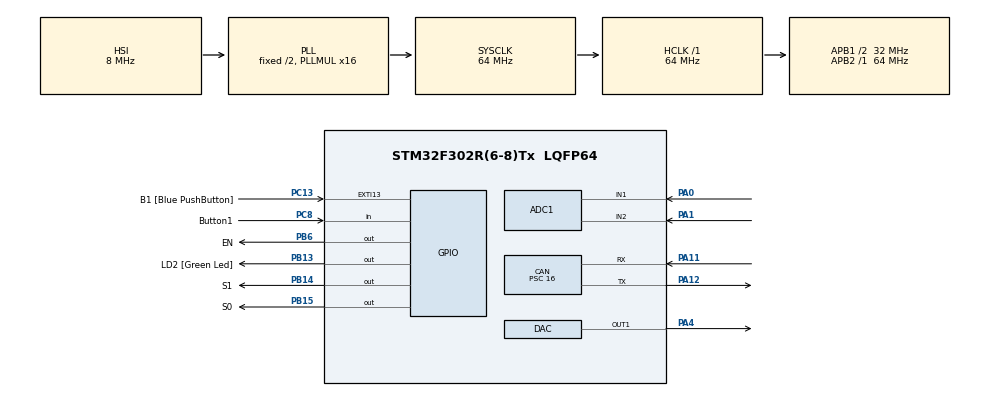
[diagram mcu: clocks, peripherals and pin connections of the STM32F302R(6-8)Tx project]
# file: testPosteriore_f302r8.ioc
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ADC1.Channel-0\#ChannelRegularConversion=ADC_CHANNEL_1
ADC1.Channel-1\#ChannelRegularConversion=ADC_CHANNEL_2
ADC1.ContinuousConvMode=ENABLE
ADC1.DMAContinuousRequests=ENABLE
ADC1.NbrOfConversion=2
ADC1.NbrOfConversionFlag=1
ADC1.Offset-0\#ChannelRegularConversion=0
ADC1.Offset-1\#ChannelRegularConversion=0
ADC1.OffsetNumber-0\#ChannelRegularConversion=ADC_OFFSET_NONE
ADC1.OffsetNumber-1\#ChannelRegularConversion=ADC_OFFSET_NONE
ADC1.Rank-0\#ChannelRegularConversion=1
ADC1.Rank-1\#ChannelRegularConversion=2
ADC1.SamplingTime-0\#ChannelRegularConversion=ADC_SAMPLETIME_61CYCLES_5
ADC1.SamplingTime-1\#ChannelRegularConversion=ADC_SAMPLETIME_61CYCLES_5
ADC1.SamplingTimeOPAMP-1\#ChannelRegularConversion=ADC_SAMPLETIME_61CYCLES_5
ADC1.SubFamily=STM32F302x8
ADC1.master=1
CAN.BS1=CAN_BS1_2TQ
CAN.CalculateBaudRate=500000
CAN.CalculateTimeBit=2000
CAN.CalculateTimeQuantum=500.0
CAN.Mode=CAN_MODE_NORMAL
CAN.Prescaler=16
Dma.ADC1.1.Direction=DMA_PERIPH_TO_MEMORY
Dma.ADC1.1.Instance=DMA1_Channel1
Dma.ADC1.1.MemDataAlignment=DMA_MDATAALIGN_HALFWORD
Dma.ADC1.1.MemInc=DMA_MINC_ENABLE
Dma.ADC1.1.Mode=DMA_CIRCULAR
Dma.ADC1.1.PeriphDataAlignment=DMA_PDATAALIGN_HALFWORD
Dma.ADC1.1.PeriphInc=DMA_PINC_DISABLE
Dma.ADC1.1.Priority=DMA_PRIORITY_LOW
Dma.DAC_CH1.0.Direction=DMA_MEMORY_TO_PERIPH
Dma.DAC_CH1.0.Instance=DMA1_Channel3
Dma.DAC_CH1.0.MemDataAlignment=DMA_MDATAALIGN_HALFWORD
Dma.DAC_CH1.0.MemInc=DMA_MINC_ENABLE
Dma.DAC_CH1.0.Mode=DMA_CIRCULAR
Dma.DAC_CH1.0.PeriphDataAlignment=DMA_PDATAALIGN_HALFWORD
Dma.DAC_CH1.0.PeriphInc=DMA_PINC_DISABLE
Dma.DAC_CH1.0.Priority=DMA_PRIORITY_LOW
Dma.Request0=DAC_CH1
Dma.Request1=ADC1
Mcu.Family=STM32F3
Mcu.Name=STM32F302R(6-8)Tx
Mcu.Package=LQFP64
NVIC.DMA1_Channel1_IRQn=true\:0\:0\:false\:false\:true\:false\:true\:true
NVIC.DMA1_Channel3_IRQn=true\:0\:0\:false\:false\:true\:false\:true\:true
NVIC.EXTI15_10_IRQn=true\:0\:0\:false\:false\:true\:true\:true\:true
NVIC.PriorityGroup=NVIC_PRIORITYGROUP_0
PA0.Mode=IN1-Single-Ended
PA0.Signal=ADC1_IN1
PA1.Mode=IN2-Single-Ended
PA1.Signal=ADC1_IN2
PA11.Mode=CAN_Activate
PA11.Signal=CAN_RX
PA12.Mode=CAN_Activate
PA12.Signal=CAN_TX
PA4.Signal=COMP_DAC1_group
PB13.GPIO_Label=LD2 [Green Led]
PB13.Signal=GPIO_Output
PB14.GPIO_Label=S1
PB14.Signal=GPIO_Output
PB15.GPIO_Label=S0
PB15.Signal=GPIO_Output
PB6.GPIO_Label=EN
PB6.Signal=GPIO_Output
PC13.GPIO_Label=B1 [Blue PushButton]
PC13.GPIO_ModeDefaultEXTI=GPIO_MODE_IT_FALLING
PC13.Signal=GPXTI13
PC8.GPIO_Label=Button1
PC8.Signal=GPIO_Input
ProjectManager.HeapSize=0x200
ProjectManager.StackSize=0x400
ProjectManager.TargetToolchain=STM32CubeIDE
RCC.ADC12PRES=RCC_ADC1PLLCLK_DIV64
RCC.AHBFreq_Value=64000000
RCC.APB1CLKDivider=RCC_HCLK_DIV2
RCC.APB1Freq_Value=32000000
RCC.APB1TimFreq_Value=64000000
RCC.APB2Freq_Value=64000000
RCC.APB2TimFreq_Value=64000000
RCC.CortexFreq_Value=64000000
RCC.HCLKFreq_Value=64000000
RCC.HSE_VALUE=8000000
RCC.HSI_VALUE=8000000
RCC.LSE_VALUE=32768
RCC.PLLM=8
RCC.PLLMUL=RCC_PLL_MUL16
RCC.PLLN=336
RCC.PLLP=RCC_PLLP_DIV4
RCC.PLLQ=7
RCC.RCC_PLLsource_Clock_Source_FROM_HSE=RCC_HSE_PREDIV_DIV2
RCC.SYSCLKFreq_VALUE=64000000
RCC.SYSCLKSourceVirtual=RCC_SYSCLKSOURCE_PLLCLK
RCC.USBFreq_Value=64000000
SH.COMP_DAC1_group.0=DAC_OUT1,DAC_OUT1
board=NUCLEO-F302R8

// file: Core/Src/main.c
/* USER CODE BEGIN Header */
/**
  ******************************************************************************
  * @file           : main.c
  * @brief          : Main program body
  ******************************************************************************
  * @attention
  *
  * Copyright (c) 2022 STMicroelectronics.
  * All rights reserved.
  *
  * This software is licensed under terms that can be found in the LICENSE file
  * in the root directory of this software component.
  * If no LICENSE file comes with this software, it is provided AS-IS.
  *
  ******************************************************************************
  */
/* USER CODE END Header */
#include "main.h"

/* USER CODE BEGIN Includes */
#include "mmr_bb_manager.h"
/* USER CODE END Includes */

 ADC_HandleTypeDef hadc1;
DMA_HandleTypeDef hdma_adc1;

CAN_HandleTypeDef hcan;

DAC_HandleTypeDef hdac;
DMA_HandleTypeDef hdma_dac_ch1;

/* USER CODE BEGIN PV */
int tmp[3] = {};
HalStatus status = HAL_ERROR;
/* USER CODE END PV */

void SystemClock_Config(void);
static void MX_GPIO_Init(void);
static void MX_ADC1_Init(void);
static void MX_DMA_Init(void);
static void MX_DAC_Init(void);
static void MX_CAN_Init(void);

int main(void)
{

  /* MCU Configuration--------------------------------------------------------*/

  /* Reset of all peripherals, Initializes the Flash interface and the Systick. */
  HAL_Init();

  /* Configure the system clock */
  SystemClock_Config();

  /* Initialize all configured peripherals */
  MX_GPIO_Init();
  MX_DMA_Init();
  MX_DAC_Init();
  MX_ADC1_Init();
  MX_CAN_Init();
  /* USER CODE BEGIN 2 */
  if (MMR_BB_initManager(&hcan, &hadc1, &hdac) != HAL_OK) {
	  Error_Handler();
  }
  /* USER CODE END 2 */

  /* Infinite loop */
  /* USER CODE BEGIN WHILE */
  while (1)
  {
	  if (MMR_BB_startManager() != HAL_OK) {
		  Error_Handler();
	  }
    /* USER CODE END WHILE */

  }
}

void SystemClock_Config(void)
{
  RCC_OscInitTypeDef RCC_OscInitStruct = {0};
  RCC_ClkInitTypeDef RCC_ClkInitStruct = {0};
  RCC_PeriphCLKInitTypeDef PeriphClkInit = {0};

  /** Initializes the RCC Oscillators according to the specified parameters
  * in the RCC_OscInitTypeDef structure.
  */
  RCC_OscInitStruct.OscillatorType = RCC_OSCILLATORTYPE_HSI;
  RCC_OscInitStruct.HSIState = RCC_HSI_ON;
  RCC_OscInitStruct.HSICalibrationValue = RCC_HSICALIBRATION_DEFAULT;
  RCC_OscInitStruct.PLL.PLLState = RCC_PLL_ON;
  RCC_OscInitStruct.PLL.PLLSource = RCC_PLLSOURCE_HSI;
  RCC_OscInitStruct.PLL.PLLMUL = RCC_PLL_MUL16;
  if (HAL_RCC_OscConfig(&RCC_OscInitStruct) != HAL_OK)
  {
    Error_Handler();
  }

  /** Initializes the CPU, AHB and APB buses clocks
  */
  RCC_ClkInitStruct.ClockType = RCC_CLOCKTYPE_HCLK|RCC_CLOCKTYPE_SYSCLK
                              |RCC_CLOCKTYPE_PCLK1|RCC_CLOCKTYPE_PCLK2;
  RCC_ClkInitStruct.SYSCLKSource = RCC_SYSCLKSOURCE_PLLCLK;
  RCC_ClkInitStruct.AHBCLKDivider = RCC_SYSCLK_DIV1;
  RCC_ClkInitStruct.APB1CLKDivider = RCC_HCLK_DIV2;
  RCC_ClkInitStruct.APB2CLKDivider = RCC_HCLK_DIV1;

  if (HAL_RCC_ClockConfig(&RCC_ClkInitStruct, FLASH_LATENCY_2) != HAL_OK)
  {
    Error_Handler();
  }
  PeriphClkInit.PeriphClockSelection = RCC_PERIPHCLK_ADC1;
  PeriphClkInit.Adc1ClockSelection = RCC_ADC1PLLCLK_DIV64;

  if (HAL_RCCEx_PeriphCLKConfig(&PeriphClkInit) != HAL_OK)
  {
    Error_Handler();
  }
}

static void MX_ADC1_Init(void)
{

  ADC_ChannelConfTypeDef sConfig = {0};

  /** Common config
  */
  hadc1.Instance = ADC1;
  hadc1.Init.ClockPrescaler = ADC_CLOCK_ASYNC_DIV1;
  hadc1.Init.Resolution = ADC_RESOLUTION_12B;
  hadc1.Init.ScanConvMode = ADC_SCAN_ENABLE;
  hadc1.Init.ContinuousConvMode = ENABLE;
  hadc1.Init.DiscontinuousConvMode = DISABLE;
  hadc1.Init.ExternalTrigConvEdge = ADC_EXTERNALTRIGCONVEDGE_NONE;
  hadc1.Init.ExternalTrigConv = ADC_SOFTWARE_START;
  hadc1.Init.DataAlign = ADC_DATAALIGN_RIGHT;
  hadc1.Init.NbrOfConversion = 2;
  hadc1.Init.DMAContinuousRequests = ENABLE;
  hadc1.Init.EOCSelection = ADC_EOC_SINGLE_CONV;
  hadc1.Init.LowPowerAutoWait = DISABLE;
  hadc1.Init.Overrun = ADC_OVR_DATA_OVERWRITTEN;
  if (HAL_ADC_Init(&hadc1) != HAL_OK)
  {
    Error_Handler();
  }

  /** Configure Regular Channel
  */
  sConfig.Channel = ADC_CHANNEL_1;
  sConfig.Rank = ADC_REGULAR_RANK_1;
  sConfig.SingleDiff = ADC_SINGLE_ENDED;
  sConfig.SamplingTime = ADC_SAMPLETIME_61CYCLES_5;
  sConfig.OffsetNumber = ADC_OFFSET_NONE;
  sConfig.Offset = 0;
  if (HAL_ADC_ConfigChannel(&hadc1, &sConfig) != HAL_OK)
  {
    Error_Handler();
  }

  /** Configure Regular Channel
  */
  sConfig.Channel = ADC_CHANNEL_2;
  sConfig.Rank = ADC_REGULAR_RANK_2;
  if (HAL_ADC_ConfigChannel(&hadc1, &sConfig) != HAL_OK)
  {
    Error_Handler();
  }

}

static void MX_CAN_Init(void)
{

  hcan.Instance = CAN;
  hcan.Init.Prescaler = 16;
  hcan.Init.Mode = CAN_MODE_NORMAL;
  hcan.Init.SyncJumpWidth = CAN_SJW_1TQ;
  hcan.Init.TimeSeg1 = CAN_BS1_2TQ;
  hcan.Init.TimeSeg2 = CAN_BS2_1TQ;
  hcan.Init.TimeTriggeredMode = DISABLE;
  hcan.Init.AutoBusOff = DISABLE;
  hcan.Init.AutoWakeUp = DISABLE;
  hcan.Init.AutoRetransmission = DISABLE;
  hcan.Init.ReceiveFifoLocked = DISABLE;
  hcan.Init.TransmitFifoPriority = DISABLE;
  if (HAL_CAN_Init(&hcan) != HAL_OK)
  {
    Error_Handler();
  }

}

static void MX_DAC_Init(void)
{

  DAC_ChannelConfTypeDef sConfig = {0};

  /** DAC Initialization
  */
  hdac.Instance = DAC;
  if (HAL_DAC_Init(&hdac) != HAL_OK)
  {
    Error_Handler();
  }

  /** DAC channel OUT1 config
  */
  sConfig.DAC_Trigger = DAC_TRIGGER_NONE;
  sConfig.DAC_OutputBuffer = DAC_OUTPUTBUFFER_ENABLE;
  if (HAL_DAC_ConfigChannel(&hdac, &sConfig, DAC_CHANNEL_1) != HAL_OK)
  {
    Error_Handler();
  }

}

static void MX_DMA_Init(void)
{

  /* DMA controller clock enable */
  __HAL_RCC_DMA1_CLK_ENABLE();

  /* DMA interrupt init */
  /* DMA1_Channel1_IRQn interrupt configuration */
  HAL_NVIC_SetPriority(DMA1_Channel1_IRQn, 0, 0);
  HAL_NVIC_EnableIRQ(DMA1_Channel1_IRQn);
  /* DMA1_Channel3_IRQn interrupt configuration */
  HAL_NVIC_SetPriority(DMA1_Channel3_IRQn, 0, 0);
  HAL_NVIC_EnableIRQ(DMA1_Channel3_IRQn);

}

static void MX_GPIO_Init(void)
{
  GPIO_InitTypeDef GPIO_InitStruct = {0};

  /* GPIO Ports Clock Enable */
  __HAL_RCC_GPIOC_CLK_ENABLE();
  __HAL_RCC_GPIOA_CLK_ENABLE();
  __HAL_RCC_GPIOB_CLK_ENABLE();

  /*Configure GPIO pin Output Level */
  HAL_GPIO_WritePin(GPIOB, LD2_Pin|S1_Pin|S0_Pin|EN_Pin, GPIO_PIN_RESET);

  /*Configure GPIO pin : B1_Pin */
  GPIO_InitStruct.Pin = B1_Pin;
  GPIO_InitStruct.Mode = GPIO_MODE_IT_FALLING;
  GPIO_InitStruct.Pull = GPIO_NOPULL;
  HAL_GPIO_Init(B1_GPIO_Port, &GPIO_InitStruct);

  /*Configure GPIO pins : LD2_Pin S1_Pin S0_Pin EN_Pin */
  GPIO_InitStruct.Pin = LD2_Pin|S1_Pin|S0_Pin|EN_Pin;
  GPIO_InitStruct.Mode = GPIO_MODE_OUTPUT_PP;
  GPIO_InitStruct.Pull = GPIO_NOPULL;
  GPIO_InitStruct.Speed = GPIO_SPEED_FREQ_LOW;
  HAL_GPIO_Init(GPIOB, &GPIO_InitStruct);

  /*Configure GPIO pin : Button1_Pin */
  GPIO_InitStruct.Pin = Button1_Pin;
  GPIO_InitStruct.Mode = GPIO_MODE_INPUT;
  GPIO_InitStruct.Pull = GPIO_NOPULL;
  HAL_GPIO_Init(Button1_GPIO_Port, &GPIO_InitStruct);

  /* EXTI interrupt init*/
  HAL_NVIC_SetPriority(EXTI15_10_IRQn, 0, 0);
  HAL_NVIC_EnableIRQ(EXTI15_10_IRQn);

}

/* USER CODE BEGIN 4 */
void HAL_GPIO_EXTI_Callback(uint16_t GPIO_Pin) {
	MMR_BB_changeDrivingMode();
}

void EXTI4_15_IRQHandler() {
	HAL_GPIO_EXTI_IRQHandler(GPIO_PIN_10);
}
/* USER CODE END 4 */

void Error_Handler(void)
{
  __disable_irq();
  while (1)
  {
  }
}
